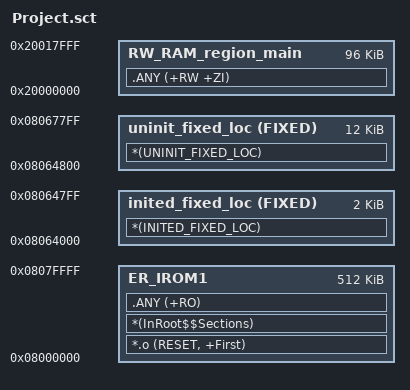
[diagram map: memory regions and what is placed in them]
; *************************************************************
; *** Scatter-Loading Description File generated by uVision ***
; *************************************************************

LR_IROM1 0x08000000 0x80000  {    ; load region size_region
  ER_IROM1 0x08000000 0x80000  {  ; load address = execution address
   *.o (RESET, +First)
   *(InRoot$$Sections)
   .ANY (+RO)
  }
   inited_fixed_loc  0x08064000 FIXED 0x800  {  ; load address = execution address
  *(INITED_FIXED_LOC)
  }
   uninit_fixed_loc 0x08064800 FIXED 0x3000  {  ; load address = execution address
  *(UNINIT_FIXED_LOC)
   }
   RW_RAM_region_main 0x20000000 0x18000  {  ; RW data
   .ANY (+RW +ZI)
   
  }
}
